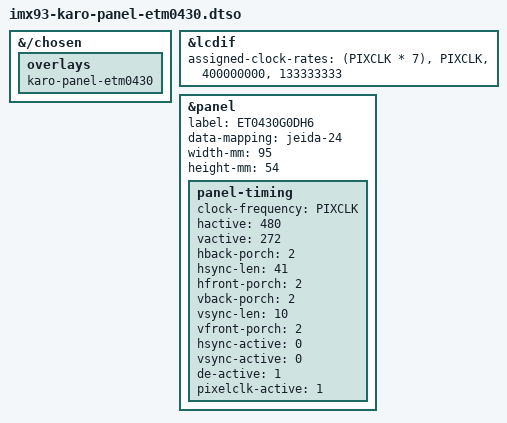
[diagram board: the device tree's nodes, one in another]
// SPDX-License-Identifier: (GPL-2.0 OR MIT)
/*
 * Copyright 2023 Lothar Waßmann <LW@KARO-electronics.de>
 *
 */

/dts-v1/;

/plugin/;

&{/chosen} {
	overlays {
		karo-panel-etm0430;
	};
};

#define PIXCLK 9000000

&lcdif {
	assigned-clock-rates = <(PIXCLK * 7)>, <PIXCLK>, <400000000>, <133333333>;
};

&panel {
	label = "ET0430G0DH6";
	data-mapping = "jeida-24";
	width-mm = <95>;
	height-mm = <54>;
	status = "okay";

	panel-timing {
		clock-frequency = <PIXCLK>;
		hactive = <480>;
		vactive = <272>;
		hback-porch = <2>;
		hsync-len = <41>;
		hfront-porch = <2>;
		vback-porch = <2>;
		vsync-len = <10>;
		vfront-porch = <2>;
		hsync-active = <0>;
		vsync-active = <0>;
		de-active = <1>;
		pixelclk-active = <1>;
	};
};
